# sdio_core_secure register map
Vendor: Texas Instruments
Peripheral module from a debugger description file (folder CC35X1).
Registers are 32-bit, read-only, reset 0x0 unless marked. A register's access mark holds for its fields unless they carry their own. Offsets are as the file gives them; lines under a group give offsets from that group; [hi:lo] are bit positions; {n}, {i} and the like mark numbered series; 'fields as' and 'values as' point back to an identical list; <NAME> marks a mode.

## sdio_core_secure
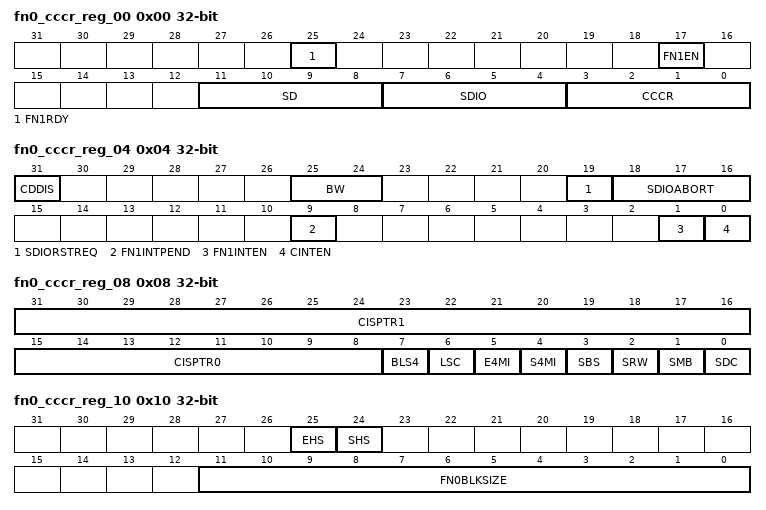
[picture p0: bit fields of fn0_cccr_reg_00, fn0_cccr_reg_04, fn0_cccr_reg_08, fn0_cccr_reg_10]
0x00 fn0_cccr_reg_00 access per field reset not defined
  [25] FN1RDY rw — Function 1 Ready
  [17] FN1EN rw — Enable Function 1
  [11:8] SD ro — SD Format Version number
  [7:4] SDIO ro — SDIO Specification Revision number
  [3:0] CCCR ro — 4 CCCRx bits defines the version used by CCCR and the FBR format it supports
0x04 fn0_cccr_reg_04 access per field
  [31] CDDIS rw — Connect/Disconnect (0/1) the pull-up resistor on SDIO data line 3
  [25:24] BW rw — Defines SDIO data bus width
  [19] SDIORSTREQ wo — reset sdio IP due to a SDIO Card Reset command
  [18:16] SDIOABORT wo — Abort read or write transaction and free the SDIO bus.
  [9] FN1INTPEND ro — Interrupt pending for function 1
  [1] FN1INTEN rw — Interrupt Enable for function 1
  [0] CINTEN rw — Interrupt Enable controller
0x08 fn0_cccr_reg_08 access per field reset not defined
  [31:16] CISPTR1 ro — Bits 23:8 of cards common CIS pointer
  [15:8] CISPTR0 ro — Bits 7:0 of cards common CIS pointer
  [7] BLS4 ro — 4 bit support for low speed cards
  [6] LSC ro — Card is a low speed card
  [5] E4MI rw — Enable interrupt between blocks of data in SDIO 4 bit mode
  [4] S4MI ro — Supports interrupt between blocks of data in SDIO 4 bit mode
  [3] SBS ro — Card support Suspend/Resume
  [2] SRW ro — Card support read wait
  [1] SMB ro — Card support Multi-Block
  [0] SDC ro — Card support direct commands during data transfer
0x10 fn0_cccr_reg_10 access per field reset not defined
  [25] EHS rw — Enable High Speed
  [24] SHS ro — Support High Speed
  [11:0] FN0BLKSIZE rw — Function 0 block size
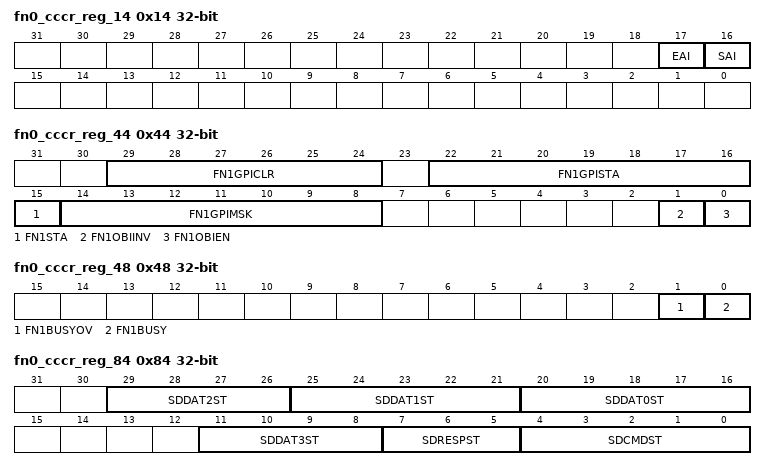
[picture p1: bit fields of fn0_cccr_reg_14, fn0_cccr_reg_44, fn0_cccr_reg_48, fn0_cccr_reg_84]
0x14 fn0_cccr_reg_14 access per field reset not defined
  [17] EAI rw — Enable Asynchronous Interrupt: Enable bit of asynchronous interrupt. When Sai is set to 0, writing to this bit is ignored and always indicates 0. This bit is effective in in SD 4-bit mode.
  [16] SAI ro — Support Asynchronous Interrupt: Support bit of Asynchronous Interrupt. If the card supports asynchronous interrupt in SD 4-bit mode, this bit is set to 1.
0x40 fn0_cccr_reg_40 access per field reset not defined
  [16] FN1ELPSTA rw — Enter Low Power mode Status bit
0x44 fn0_cccr_reg_44 access per field reset not defined
  [29:24] FN1GPICLR wo — General Purpose clear Interrupt sources. Write "1" to clear the desire source. bit 0 - ELP signal transition from "0" to "1" bit 1 - ELP signal transition from "1" to "0" bit 2 - Host write to IOE1 register (Function 0 address 0x2) bit 3 - Host write to function 0 CCCR area bit 4 - Function 1 data block completion bit 5 - Function 1 data block with CRC error
  [22:16] FN1GPISTA ro — General Purpose Interrupt sources status. bit 0 - ELP signal transition from "0" to "1" bit 1 - ELP signal transition from "1" to "0" bit 2 - Host write to IOE1 register (Function 0 address 0x2) bit 3 - Host write to function 0 CCCR area bit 4 - Function 1 data block completion bit 5 - Function 1 data block with CRC error bit 6 - Autonomous mode: cmd 53 valid WR command to data FIFO
  [15] FN1STA ro — Function 1 interrupt status.
  [14:8] FN1GPIMSK rw — General Purpose Interrupt source mask. bit 0 - ELP signal transition from "0" to "1" bit 1 - ELP signal transition from "1" to "0" bit 2 - Host write to IOE1 register (Function 0 address 0x2) bit 3 - Host write to function 0 CCCR area bit 4 - Function 1 data block completion bit 5 - Function 1 data block with CRC error bit 6 - Autonomous mode: cmd 53 valid WR command to data FIFO
  [1] FN1OBIINV rw — Invert Out Band Interrupt polarity
  [0] FN1OBIEN rw — Enable Out Band Interrupt
0x48 fn0_cccr_reg_48 access per field
  [1] FN1BUSYOV rw — Override function 1 busy signal value. 0 - Do not override. 1 - Override.
  [0] FN1BUSY rw — Set function 1 busy signal override value
0x60 fn0_cccr_reg_60 reset 0x30001
0x64 fn0_cccr_reg_64 reset not defined — Any read from this register clears the all GPI bits
0x68 fn0_cccr_reg_68 reset not defined
  [21:16] CMDERR — Bit map: 0 - Address error 1 - Function number error 2 - General error 3 - Illegal command error 4 - CRC error 5 - Out of range error
0x80 fn0_cccr_reg_80 access per field reset 0xFFFFC0
  [23:0] OCR rw — Bits 23:0 of Operation Conditions Register
0x84 fn0_cccr_reg_84 reset not defined
  [29:26] SDDAT2ST — Data line 2 state machine
  [25:21] SDDAT1ST — Data line 1 state machine
  [20:16] SDDAT0ST — Data line 0 state machine
  [11:8] SDDAT3ST — Data line 3 state machine
  [7:5] SDRESPST — Response state machine
  [4:0] SDCMDST — SDIO command decoder state machine
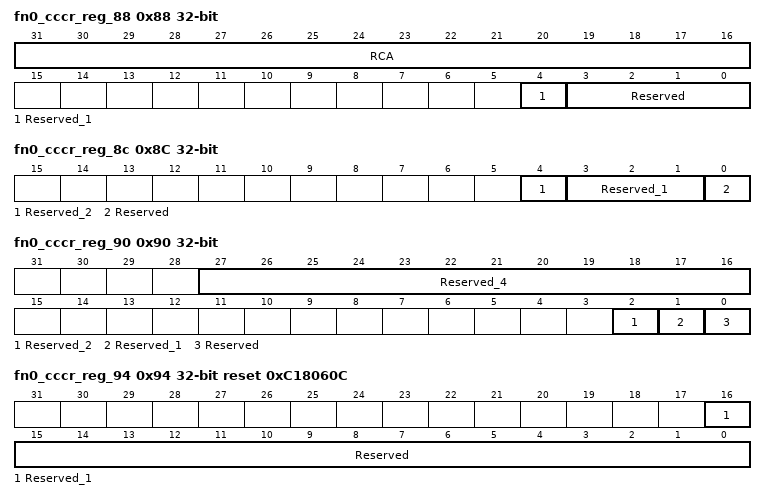
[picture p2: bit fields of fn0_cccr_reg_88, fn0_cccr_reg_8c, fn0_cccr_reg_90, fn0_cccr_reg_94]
0x88 fn0_cccr_reg_88
  [31:16] RCA — Relative Card Address
  [4] Reserved_1 — WSPI error status
  [3:0] Reserved — WSPI command state machine
0x8C fn0_cccr_reg_8c — WSPI is not supported in Osprey Mx. read only, reserved as zero
  [4] Reserved_2 — Override Fixed Busy Response settings
  [3:1] Reserved_1 — Set the number of busy words
  [0] Reserved — Enable WSPI Fixed Busy Response mechanism
0x90 fn0_cccr_reg_90 — WSPI is not supported in Osprey Mx. read only, reserved as zero
  [27:16] Reserved_4 — EOT length threshold
  [2] Reserved_2 — Disable transaction address threshold comparison
  [1] Reserved_1 — Disable transaction length threshold comparison
  [0] Reserved — Enable EOT interrupt
0x94 fn0_cccr_reg_94 reset 0xC18060C (reset mask 0xFFFEFFFF) — WSPI is not supported in Osprey Mx. read only, reserved as zero
  [16] Reserved_1 — EOT base address MSB threshold
  [15:0] Reserved — EOT base address LSB threshold. The value will be updated only after write transaction to function 0 address 0x4B.
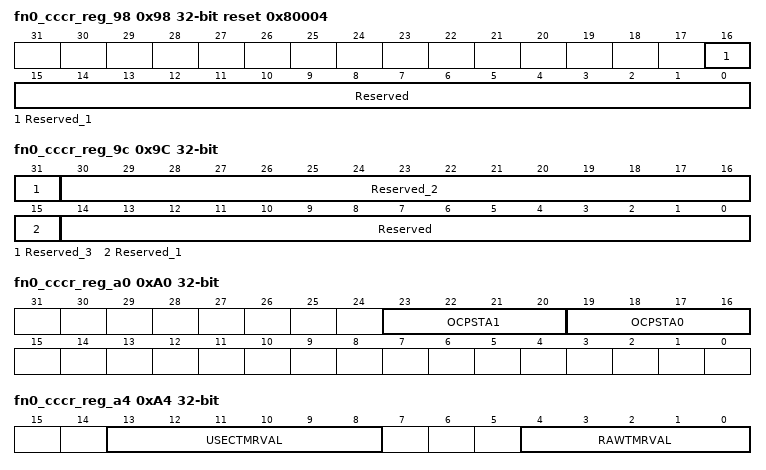
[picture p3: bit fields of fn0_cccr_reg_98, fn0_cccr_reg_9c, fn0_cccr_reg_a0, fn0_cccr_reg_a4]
0x98 fn0_cccr_reg_98 reset 0x80004 (reset mask 0xFFFEFFFF) — WSPI is not supported in Osprey Mx. read only, reserved as zero
  [16] Reserved_1 — EOT offset address MSB threshold
  [15:0] Reserved — EOT offset address LSB threshold. The value will be updated only after write transaction to function 0 address 0x4D.
0x9C fn0_cccr_reg_9c — WSPI is not supported in Osprey Mx. read only, reserved as zero
  [31] Reserved_3 — EOT hit status. Clear on read. 0 - Old 1 - New
  [30:16] Reserved_2 — EOT read address hit
  [15] Reserved_1 — EOT hit status. Clear on read. 0 - Old 1 - New
  [14:0] Reserved — EOT write address hit
0xA0 fn0_cccr_reg_a0
  [23:20] OCPSTA1 — ocp status 7-4 OCP read command status. Clear on read
  [19:16] OCPSTA0 — ocp status 3-0 OCP write command status. Clear on read
0xA4 fn0_cccr_reg_a4 access per field reset not defined
  [13:8] USECTMRVAL rw — Set usec timer count value. This timer is running at sys_ocp_clk_aod_i clock.
  [4:0] RAWTMRVAL rw — Determine the duration between write and read request in CMD52 raw.
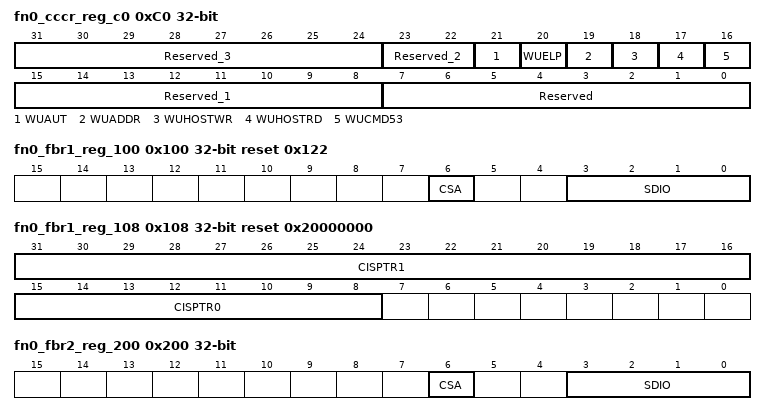
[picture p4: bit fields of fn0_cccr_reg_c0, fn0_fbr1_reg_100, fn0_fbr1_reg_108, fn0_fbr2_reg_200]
0xC0 fn0_cccr_reg_c0 rw reset not defined
  [31:24] Reserved_3 — Not in use (Previously aimed to bit[7:0] - sdio_wr_fifo_vacant_th)
  [23:22] Reserved_2 — Not in use (Previously aimed to bit[7:0] - sdio_wr_fifo_busy_th)
  [21] WUAUT — WAKEUP DUE HOST CMD AUT: 0: Do not Wakeup upon arrival of host command in an Autonomous manner 1: Wakeup due to host command arrival in an Autonomous manner (default)
  [20] WUELP — WAKEUP DUE KNOWN ADDRESS: 0: Do not wakeup due to SDIO cmd 52 or SPI wr to ELP reg (default) 1: Wakeup due to SDIO cmd 52 or SPI wr to ELP reg
  [19] WUADDR — WAKEUP DUE KNOWN ADDRESS: 0: Wakeup regardless to address parsing 1: Wakeup due to command toward known address (default)
  [18] WUHOSTWR — WAKEUP DUE HOST WR: 0: Do not Wakeup due host Write 1: Wakeup due to host Write (default)
  [17] WUHOSTRD — WAKEUP DUE HOST RD: 0: Do not wakeup due host Read 1: Wakeup due to host Read (default)
  [16] WUCMD53 — WAKEUP DUE CMD 53 ONLY: 0: Wakeup due to command 53 Or command 52 1: Wakeup due to command 53 only (default)
  [15:8] Reserved_1 — bit [0] - addr_logic_enable: 0 (disabled) - Access the actual Lx Core addresses with regions as standard SDIO/SPI transaction. The result will be either the actual data in the requested address if SDIO_SPI_WRAPPER_ACCESS_MODE_CFG register is full access enabled, or an OUT_OF_RANGE error otherwise. 1 (default value) - If receiving an SDIO/SPI transaction function 2 with well-known addresses - activate SDIO/SPI wrapper logic that is based on well-known addresses for function 2 (e.g. Ctrl or Addr). bits [7:1] - Unused
  [7:0] Reserved — bit [0] - Enable asynchronous in-band interrupt bit [1] - Force pull-up when the asynchronous in-band interrupt is in idle state bit [2] - SDIO clock idle polarity (0 = low, 1 = high) bits [7:3] - Unused
0xC4 fn0_cccr_reg_c4 reset 0x7E02000 (reset mask 0xFFFFE000) — GPI FN1 and FN2 combined register. Clear on Read. Reading this reguster clears the fn1/2_gpi_sts in 0x44/0x64 Regs respectively as well
  [6:0] FN1GPISTA — General Purpose Interrupt sources status. bit 0 - ELP signal transition from "0" to "1" bit 1 - ELP signal transition from "1" to "0" bit 2 - Host write to IOE1 register (Function 0 address 0x2) bit 3 - Host write to function 0 CCCR area bit 4 - Function 1 data block completion bit 5 - Function 1 data block with CRC error bit 6 - Autonomous mode: cmd 53 valid WR command to data FIFO
0x100 fn0_fbr1_reg_100 reset 0x122 (reset mask 0xFFFFFFBF)
  [6] CSA — Function 1 Supports CSA
  [3:0] SDIO — SDIO standard function 1 interface code
0x108 fn0_fbr1_reg_108 reset 0x20000000 (reset mask 0xFFFF0000)
  [31:16] CISPTR1 — Bits 23:8 of address pointer to function 1 CIS
  [15:8] CISPTR0 — Bits 7:0 of address pointer to function 1 CIS
0x110 fn0_fbr1_reg_110 access per field
  [11:0] FNBLKSIZE rw — function 1 block size register
0x200 fn0_fbr2_reg_200
  [6] CSA — Function 2 Supports CSA
  [3:0] SDIO — SDIO standard function 2 interface code
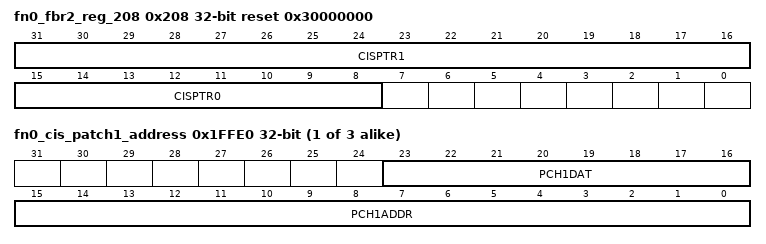
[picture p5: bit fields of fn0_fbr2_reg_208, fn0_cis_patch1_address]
0x208 fn0_fbr2_reg_208 reset 0x30000000 (reset mask 0xFFFF0000)
  [31:16] CISPTR1 — Bits 23:8 of address pointer to function 2 CIS
  [15:8] CISPTR0 — Bits 7:0 of address pointer to function 2 CIS
0x210 fn0_fbr2_reg_210 access per field
  [11:0] FNBLKSIZE rw — function 2 block size register
{0x1FFDC+4i} fn0_cis_patch{i}_address access per field (i=1..3)
  [23:16] PCH{i}DAT rw — CIS data patch {i}
  [15:0] PCH{i}ADDR rw — CIS address patch {i}
